# PRUSS1_INTC_local register map
Vendor: Texas Instruments
Peripheral module from a debugger description file (folder DRA72x).
Registers are 32-bit, access per field, reset values left out (the file's numbers can be read two ways) unless marked. A register's access mark holds for its fields unless they carry their own. Offsets are as the file gives them; lines under a group give offsets from that group; [hi:lo] are bit positions; {n}, {i} and the like mark numbered series; 'fields as' and 'values as' point back to an identical list; <NAME> marks a mode.

## PRUSS1_INTC
0x00 PRUSS_INTC_REVID ro — Revision ID Register
  [31:0] REVISION — IP Revision
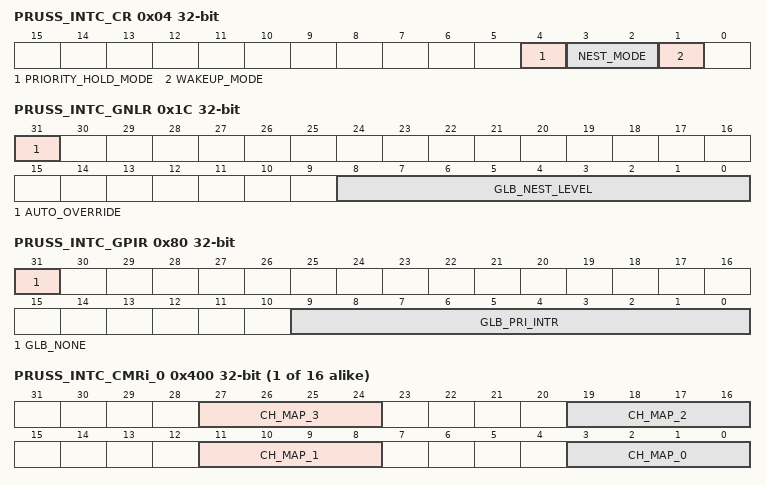
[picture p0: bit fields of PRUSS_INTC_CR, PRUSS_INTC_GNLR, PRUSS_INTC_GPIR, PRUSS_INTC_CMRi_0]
0x04 PRUSS_INTC_CR — The Control Register holds global control parameters and can forces a soft reset on the module.
  [4] PRIORITY_HOLD_MODE rw — Reserved
  [3:2] NEST_MODE rw — The nesting mode. 0 = no nesting 1 = automatic individual nesting (per host interrupt) 2 = automatic global nesting (over all host interrupts) 3 = manual nesting
  [1] WAKEUP_MODE rw — Reserved
0x10 PRUSS_INTC_GER — The Global Host Interrupt Enable Register enables all the host interrupts. Individual host interrupts are still enabled or disabled from their individual enables and are not overridden by the global enable.
  [0] ENABLE_HINT_ANY rw — The current global enable value when read. Writes set the global enable.
0x1C PRUSS_INTC_GNLR — The Global Nesting Level Register allows the checking and setting of the global nesting level across all host interrupts when automatic global nesting mode is set. The nesting level is the channel (and all of lower priority) that are nested out because of a current interrupt. This register is only available when nesting is configured.
  [31] AUTO_OVERRIDE wo — Always read as 0. Writes of 1 override the automatic nesting and set the nesting_level to the written data.
  [8:0] GLB_NEST_LEVEL rw — The current global nesting level (highest channel that is nested). Writes set the nesting level. In auto nesting mode this value is updated internally unless the auto_override bit is set.
0x20 PRUSS_INTC_SISR — The System Interrupt Status Indexed Set Register allows setting the status of an interrupt. The interrupt to set is the index value written. This sets the Raw Status Register bit of the given index.
  [9:0] STATUS_SET_INDEX wo — Writes set the status of the interrupt given in the index value. Reads return 0.
0x24 PRUSS_INTC_SICR — The System Interrupt Status Indexed Clear Register allows clearing the status of an interrupt. The interrupt to clear is the index value written. This clears the Raw Status Register bit of the given index.
  [9:0] STATUS_CLR_INDEX wo — Writes clear the status of the interrupt given in the index value. Reads return 0.
0x28 PRUSS_INTC_EISR — The System Interrupt Enable Indexed Set Register allows enabling an interrupt. The interrupt to enable is the index value written. This sets the Enable Register bit of the given index.
  [9:0] ENABLE_SET_INDEX wo — Writes set the enable of the interrupt given in the index value. Reads return 0.
0x2C PRUSS_INTC_EICR — The System Interrupt Enable Indexed Clear Register allows disabling an interrupt. The interrupt to disable is the index value written. This clears the Enable Register bit of the given index.
  [9:0] ENABLE_CLR_INDEX wo — Writes clear the enable of the interrupt given in the index value. Reads return 0.
0x34 PRUSS_INTC_HIEISR — The Host Interrupt Enable Indexed Set Register allows enabling a host interrupt output. The host interrupt to enable is the index value written. This enables the host interrupt output or triggers the output again if already enabled.
  [9:0] HINT_ENABLE_SET_INDEX rw — Writes set the enable of the host interrupt given in the index value. Reads return 0.
0x38 PRUSS_INTC_HIDISR — The Host Interrupt Enable Indexed Clear Register allows disabling a host interrupt output. The host interrupt to disable is the index value written. This disables the host interrupt output.
  [9:0] HINT_ENABLE_CLR_INDEX rw — Writes clear the enable of the host interrupt given in the index value. Reads return 0.
0x80 PRUSS_INTC_GPIR ro — The Global Prioritized Index Register shows the interrupt number of the highest priority interrupt pending across all the host interrupts.
  [31] GLB_NONE — No Interrupt is pending. Can be used by host to test for a negative value to see if no interrupts are pending.
  [9:0] GLB_PRI_INTR — The currently highest priority interrupt index pending across all the host interrupts.
0x200 PRUSS_INTC_SRSR0 rw — The System Interrupt Status Raw Set Register0 show the pending enabled status of the system interrupts 0 to 31. Software can write to the Status Set Registers to set a system interrupt without a hardware trigger. There is one bit per system interrupt.
  [31:0] RAW_STATUS_31_0 — System interrupt raw status and setting of the system interrupts 0 to 31. Reads return the raw status. Write a 1 in a bit position to set the status of the system interrupt. Writing a 0 has no effect.
0x204 PRUSS_INTC_SRSR1 rw — The System Interrupt Status Raw Set Register1 show the pending enabled status of the system interrupts 32 to 63. Software can write to the Status Set Registers to set a system interrupt without a hardware trigger. There is one bit per system interrupt.
  [31:0] RAW_STATUS_63_32 — System interrupt raw status and setting of the system interrupts 32 to 63. Reads return the raw status. Write a 1 in a bit position to set the status of the system interrupt. Writing a 0 has no effect.
0x280 PRUSS_INTC_SECR0 rw — The System Interrupt Status Enabled Clear Register0 show the pending enabled status of the system interrupts 0 to 31. Software can write to the Status Clear Registers to clear a system interrupt after it has been serviced. If a system interrupt status is not cleared then another host interrupt may not be triggered or another host interrupt may be triggered incorrectly. There is one bit per system interrupt.
  [31:0] ENA_STATUS_31_0 — System interrupt enabled status and clearing of the system interrupts 0 to 31. Reads return the enabled status (before enabling with the Enable Registers). Write a 1 in a bit position to clear the status of the system interrupt. Writing a 0 has no effect.
0x284 PRUSS_INTC_SECR1 rw — The System Interrupt Status Enabled Clear Register1 show the pending enabled status of the system interrupts 32 to 63. Software can write to the Status Clear Registers to clear a system interrupt after it has been serviced. If a system interrupt status is not cleared then another host interrupt may not be triggered or another host interrupt may be triggered incorrectly. There is one bit per system interrupt.
  [31:0] ENA_STATUS_63_32 — System interrupt enabled status and clearing of the system interrupts 32 to 63. Reads return the enabled status (before enabling with the Enable Registers). Write a 1 in a bit position to clear the status of the system interrupt. Writing a 0 has no effect.
0x300 PRUSS_INTC_ESR0 rw — The System Interrupt Enable Set Register0 enables system interrupts 0 to 31 to trigger outputs. System interrupts that are not enabled do not interrupt the host. There is a bit per system interrupt.
  [31:0] ENABLE_SET_31_0 — System interrupt enables system interrupts 0 to 31. Read returns the enable value (0 = disabled, 1 = enabled). Write a 1 in a bit position to set that enable. Writing a 0 has no effect.
0x304 PRUSS_INTC_ERS1 rw — The System Interrupt Enable Set Register1 enables system interrupts 32 to 63 to trigger outputs. System interrupts that are not enabled do not interrupt the host. There is a bit per system interrupt.
  [31:0] ENABLE_SET_63_32 — System interrupt enables system interrupts 32 to 63. Read returns the enable value (0 = disabled, 1 = enabled). Write a 1 in a bit position to set that enable. Writing a 0 has no effect.
0x380 PRUSS_INTC_ECR0 wo — The System Interrupt Enable Clear Register0 disables system interrupts 0 to 31 to map to channels. System interrupts that are not enabled do not interrupt the host. There is a bit per system interrupt.
  [31:0] ENABLE_CLR_31_0 — System interrupt enables system interrupts 0 to 31. Write a 1 in a bit position to clear that enable. Writing a 0 has no effect.
0x384 PRUSS_INTC_ECR1 wo — The System Interrupt Enable Clear Register1 disables system interrupts 32 to 63 to map to channels. System interrupts that are not enabled do not interrupt the host. There is a bit per system interrupt.
  [31:0] ENABLE_CLR_63_32 — System interrupt enables system interrupts 32 to 63. Write a 1 in a bit position to clear that enable. Writing a 0 has no effect.
{0x400+4i} PRUSS_INTC_CMRi_{i} (i=0..15) — There are 16 identical CMR registers ( i=0 to 15). The Channel Map Register_i specify the channel for the system interrupts k to k+3, where k=4*i. There is one register per 4 system interrupts.
  [27:24] CH_MAP_3 rw — Sets the channel for the system interrupt (k+3). Where k=i*4
  [19:16] CH_MAP_2 rw — Sets the channel for the system interrupt (k+2). Where k=i*4
  [11:8] CH_MAP_1 rw — Sets the channel for the system interrupt (k+1). Where k=i*4
  [3:0] CH_MAP_0 rw — Sets the channel for the system interrupt k. Where k=i*4
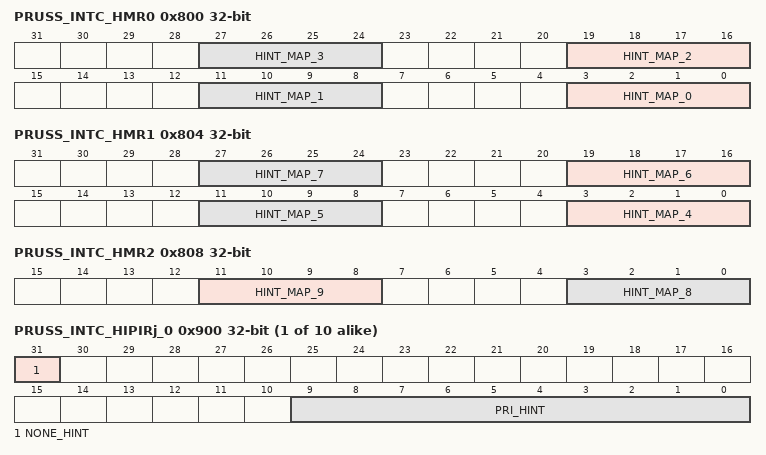
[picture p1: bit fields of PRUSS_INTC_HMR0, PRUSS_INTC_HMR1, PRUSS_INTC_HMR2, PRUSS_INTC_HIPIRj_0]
0x800 PRUSS_INTC_HMR0 — The Host Interrupt Map Register0 define the host interrupt for channels 0 to 3. There is one register per 4 channels. Channels with forced host interrupt mappings will have their fields read-only.
  [8n+3:8n] HINT_MAP_{n} rw (n=0..3) — HOST INTERRUPT MAP FOR CHANNEL {n}
0x804 PRUSS_INTC_HMR1 — The Host Interrupt Map Register1 define the host interrupt for channels 4 to 7. There is one register per 4 channels. Chan_statusnels with forced host interrupt mappings will have their fields read-only.
  [8n-29:8n-32] HINT_MAP_{n} rw (n=4..7) — HOST INTERRUPT MAP FOR CHANNEL {n}
0x808 PRUSS_INTC_HMR2 — The Host Interrupt Map Register2 define the host interrupt for channels 8 to 9. There is one register per 4 channels. Channels with forced host interrupt mappings will have their fields read-only.
  [11:8] HINT_MAP_9 rw — HOST INTERRUPT MAP FOR CHANNEL 9
  [3:0] HINT_MAP_8 rw — HOST INTERRUPT MAP FOR CHANNEL 8
{0x900+4i} PRUSS_INTC_HIPIRj_{i} ro (i=0..9) — The Host Interrupt Prioritized Index Register_j (where j=0 to 9) shows the highest priority current pending interrupt for the host interrupt j. There is one register per host interrupt.
  [31] NONE_HINT — No pending interrupt.
  [9:0] PRI_HINT — HOST INT j PRIORITIZED INTERRUPT. Interrupt number of the highest priority pending interrupt for this host interrupt.
0xD00 PRUSS_INTC_SIPR0 rw — The System Interrupt Polarity Register0 define the polarity of the system interrupts 0 to 31. There is a polarity for each system interrupt. The polarity of all system interrupts is active high; always write 1 to the bits of this register.
  [31:0] POLARITY_31_0 — Interrupt polarity of the system interrupts 0 to 31. 0 = active low. 1 = active high.
0xD04 PRUSS_INTC_SIPR1 rw — The System Interrupt Polarity Register1 define the polarity of the system interrupts 32 to 63. There is a polarity for each system interrupt. The polarity of all system interrupts is active high; always write 1 to the bits of this register.
  [31:0] POLARITY_63_32 — Interrupt polarity of the system interrupts 32 to 63. 0 = active low. 1 = active high.
0xD80 PRUSS_INTC_SITR0 rw — The System Interrupt Type Register0 define the type of the system interrupts 0 to 31. There is a type for each system interrupt. The type of all system interrupts is pulse; always write 0 to the bits of this register.
  [31:0] TYPE_31_0 — Interrupt type of the system interrupts 0 to 31. 0 = level or pulse interrupt. 1 = edge interrupt (required edge detect).
0xD84 PRUSS_INTC_SITR1 rw — The System Interrupt Type Register1 define the type of the system interrupts 32 to 63. There is a type for each system interrupt. The type of all system interrupts is pulse; always write 0 to the bits of this register.
  [31:0] TYPE_63_32 — Interrupt type of the system interrupts 32 to 63. 0 = level or pulse interrupt. 1 = edge interrupt (required edge detect).
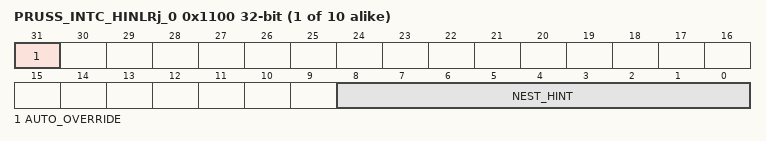
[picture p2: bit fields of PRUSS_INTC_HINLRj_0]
{0x1100+4i} PRUSS_INTC_HINLRj_{i} (i=0..9) — The Host Interrupt Nesting Level Register_j (where j=0 to 9) display and control the nesting level for host interrupt j. The nesting level controls which channel and lower priority channels are nested. There is one register per host interrupt.
  [31] AUTO_OVERRIDE wo — Reads return 0. Writes of a 1 override the auto updating of the nesting_level and use the write data.
  [8:0] NEST_HINT rw — Reads return the current nesting level for the host interrupt. Writes set the nesting level for the host interrupt. In auto mode the value is updated internally unless the auto_override is set and then the write data is used.
0x1500 PRUSS_INTC_HIER — The Host Interrupt Enable Registers enable or disable individual host interrupts. These work separately from the global enables. There is one bit per host interrupt. These bits are updated when writing to the Host Interrupt Enable Index Set and Host Interrupt Enable Index Clear registers.
  [9:0] ENABLE_HINT rw — The enable of the host interrupts (one per bit). 0 = disabled 1 = enabled
